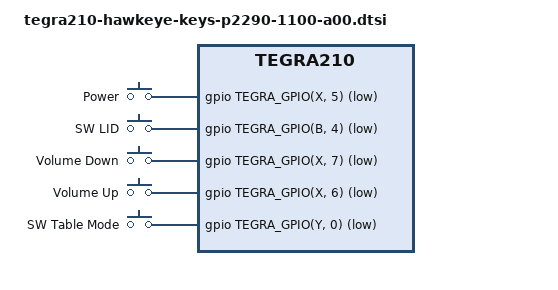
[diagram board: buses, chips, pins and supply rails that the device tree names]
/*
 * Copyright (c) 2014, NVIDIA CORPORATION.  All rights reserved.
 *
 * This program is free software; you can redistribute it and/or modify
 * it under the terms of the GNU General Public License as published by
 * the Free Software Foundation; either version 2 of the License, or
 * (at your option) any later version.
 *
 * This program is distributed in the hope that it will be useful, but WITHOUT
 * ANY WARRANTY; without even the implied warranty of MERCHANTABILITY or
 * FITNESS FOR A PARTICULAR PURPOSE.  See the GNU General Public License for
 * more details.
 *
 * You should have received a copy of the GNU General Public License
 * along with this program.  If not, see <http://www.gnu.org/licenses/>.
*/

#include <dt-bindings/gpio/tegra-gpio.h>
#include <dt-bindings/input/input.h>

/ {
	gpio-keys {
		compatible = "gpio-keys";
		gpio-keys,name = "gpio-keys";

		power {
			label = "Power";
			gpios = <&gpio TEGRA_GPIO(X, 5) GPIO_ACTIVE_LOW>;
			linux,code = <KEY_POWER>;
			gpio-key,wakeup;
		};

		sw_lid {
			label = "SW LID";
			gpios = <&gpio TEGRA_GPIO(B, 4) GPIO_ACTIVE_LOW>;
			linux,code = <SW_LID>;
			linux,input-type = <EV_SW>;
			gpio-key,wakeup;
			debounce-interval = <300>;
		};

		volume_down {
			label = "Volume Down";
			gpios = <&gpio TEGRA_GPIO(X, 7) GPIO_ACTIVE_LOW>;
			linux,code = <KEY_VOLUMEDOWN>;
		};

		volume_up {
			label = "Volume Up";
			gpios = <&gpio TEGRA_GPIO(X, 6) GPIO_ACTIVE_LOW>;
			linux,code = <KEY_VOLUMEUP>;
		};

		sw_table_mode {
			label = "SW Table Mode";
			gpios = <&gpio TEGRA_GPIO(Y, 0) GPIO_ACTIVE_LOW>;
			linux,code = <SW_TABLET_MODE>;
			linux,input-type = <EV_SW>;
			gpio-key,wakeup;
		};
	};
};
